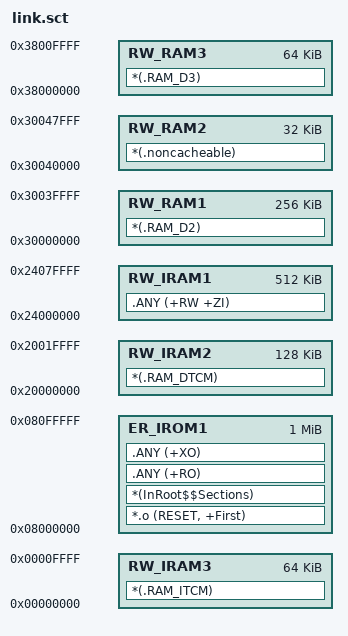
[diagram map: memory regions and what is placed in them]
; *************************************************************
; *** Scatter-Loading Description File generated by uVision ***
; *************************************************************

LR_IROM1 0x08000000 0x00100000  {    ; load region size_region
    ER_IROM1 0x08000000 0x00100000  {  ; load address = execution address
        *.o (RESET, +First)
        *(InRoot$$Sections)
        .ANY (+RO)
        .ANY (+XO)
    }
    
    ; RW data - 512KB AXI SRAM
    RW_IRAM1 0x24000000 0x00080000 {
        .ANY (+RW +ZI)
    }
    ; RW data - 128KB DTCM
    RW_IRAM2 0x20000000 0x00020000 {
        *(.RAM_DTCM)
    }
    ; RW data - 64KB ITCM
    RW_IRAM3 0x00000000 0x00010000 {
        *(.RAM_ITCM)
    }
    ; RW data - 128KB SRAM1(0x30000000) + 128KB SRAM2(0x3002 0000)
    RW_RAM1 0x30000000 0x00040000 {
        *(.RAM_D2)
    }
    ; RW data - 32KB SRAM3(0x30040000)
    RW_RAM2 0x30040000 0x00008000 {
        *(.noncacheable)
    }
    ; RW data - 64KB SRAM4(0x38000000)
    RW_RAM3 0x38000000 0x00010000 {
        *(.RAM_D3)
    }
}

